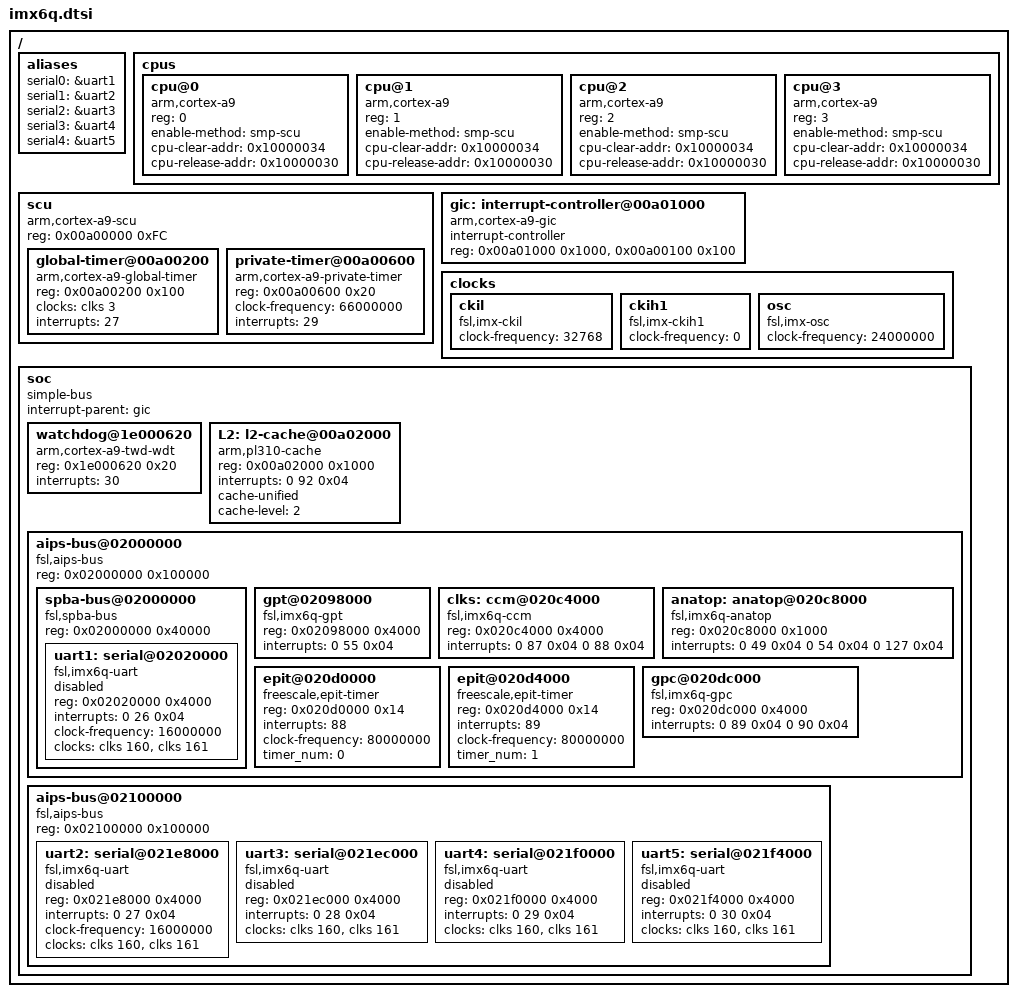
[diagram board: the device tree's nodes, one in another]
/*
 * Copyright 2014 Jimmy Durand Wesolowski - OpenWide
 * Copyright 2011 Freescale Semiconductor, Inc.
 * Copyright 2011 Linaro Ltd.
 *
 * The code contained herein is licensed under the GNU General Public
 * License. You may obtain a copy of the GNU General Public License
 * Version 2 or later at the following locations:
 *
 * http://www.opensource.org/licenses/gpl-license.html
 * http://www.gnu.org/copyleft/gpl.html
 */

/ {
	#address-cells = <1>;
	#size-cells = <1>;

	aliases {
		serial0 = &uart1;
		serial1 = &uart2;
		serial2 = &uart3;
		serial3 = &uart4;
		serial4 = &uart5;
	};

	cpus {
		#address-cells = <1>;
		#size-cells = <0>;

		cpu@0 {
			device_type = "cpu";
			compatible = "arm,cortex-a9";
			reg = <0>;
			enable-method = "smp-scu";
			cpu-clear-addr = <0x10000034>;
			cpu-release-addr = <0x10000030>;
		};

		cpu@1 {
			device_type = "cpu";
			compatible = "arm,cortex-a9";
			reg = <1>;
			enable-method = "smp-scu";
			cpu-clear-addr = <0x10000034>;
			cpu-release-addr = <0x10000030>;
		};

		cpu@2 {
			device_type = "cpu";
			compatible = "arm,cortex-a9";
			reg = <2>;
			enable-method = "smp-scu";
			cpu-clear-addr = <0x10000034>;
			cpu-release-addr = <0x10000030>;
		};

		cpu@3 {
			device_type = "cpu";
			compatible = "arm,cortex-a9";
			reg = <3>;
			enable-method = "smp-scu";
			cpu-clear-addr = <0x10000034>;
			cpu-release-addr = <0x10000030>;
		};
	};

	scu { /* Snoop Control Unit */
      		device_type = "scu";
      		compatible = "arm,cortex-a9-scu";
      		reg = <0x00a00000 0xFC>;
		#address-cells = <1>;
		#size-cells = <1>;
		ranges;

		global-timer@00a00200 {
			/* http://infocenter.arm.com/help/index.jsp?
			   topic=/com.arm.doc.ddi0407f/CIHGECHJ.html */
			/* Note that the reg attribute expects 2 sets */
			compatible = "arm,cortex-a9-global-timer";
			reg = <0x00a00200 0x100>;
			clocks = <&clks 3>;
			interrupts = <27>;
		};

		private-timer@00a00600 {
			/*http://infocenter.arm.com/help/index.jsp?
			  topic=/com.arm.doc.ddi0407f/JHBHIGCC.html */
			compatible = "arm,cortex-a9-private-timer";
			reg = <0x00a00600 0x20>;
			clock-frequency = <66000000>;
			interrupts = <29>;
		};

	};

	gic: interrupt-controller@00a01000 {
      		device_type = "pic";
		compatible = "arm,cortex-a9-gic";
		#interrupt-cells = <3>;
		#address-cells = <1>;
		#size-cells = <1>;
		interrupt-controller;
		reg = <0x00a01000 0x1000>,
		      <0x00a00100 0x100>;
	};

	clocks {
		#address-cells = <1>;
		#size-cells = <0>;

		ckil {
			compatible = "fsl,imx-ckil", "fixed-clock";
			clock-frequency = <32768>;
		};

		ckih1 {
			compatible = "fsl,imx-ckih1", "fixed-clock";
			clock-frequency = <0>;
		};

		osc {
			compatible = "fsl,imx-osc", "fixed-clock";
			clock-frequency = <24000000>;
		};
	};

	soc {
		#address-cells = <1>;
		#size-cells = <1>;
		compatible = "simple-bus";
		interrupt-parent = <&gic>;
		ranges;

		watchdog@1e000620 {
			compatible = "arm,cortex-a9-twd-wdt";
			reg = <0x1e000620 0x20>;
			interrupts = <30>;
		};

		L2: l2-cache@00a02000 {
			compatible = "arm,pl310-cache";
			reg = <0x00a02000 0x1000>;
			interrupts = <0 92 0x04>;
			cache-unified;
			cache-level = <2>;
		};

		aips-bus@02000000 { /* AIPS1 */
			compatible = "fsl,aips-bus", "simple-bus";
			#address-cells = <1>;
			#size-cells = <1>;
			reg = <0x02000000 0x100000>;
			ranges;

			spba-bus@02000000 {
				compatible = "fsl,spba-bus", "simple-bus";
				#address-cells = <1>;
				#size-cells = <1>;
				reg = <0x02000000 0x40000>;
				ranges;

				uart1: serial@02020000 {
					compatible = "fsl,imx6q-uart", "freescale,imx-uart";
					reg = <0x02020000 0x4000>;
					interrupts = <0 26 0x04>;
					clock-frequency = <16000000>;
					clocks = <&clks 160>, <&clks 161>;
					clock-names = "ipg", "per";
					status = "enabled";
				};
			};

			gpt@02098000 {
				compatible = "fsl,imx6q-gpt";
				reg = <0x02098000 0x4000>;
				interrupts = <0 55 0x04>;
			};

			clks: ccm@020c4000 {
				compatible = "fsl,imx6q-ccm";
				reg = <0x020c4000 0x4000>;
				interrupts = <0 87 0x04 0 88 0x04>;
				#clock-cells = <1>;
			};

			anatop: anatop@020c8000 {
				compatible = "fsl,imx6q-anatop", "syscon", "simple-bus";
				reg = <0x020c8000 0x1000>;
				interrupts = <0 49 0x04 0 54 0x04 0 127 0x04>;
			};

			epit@020d0000 {
				device_type = "epit1";
				compatible = "freescale,epit-timer";
				reg = <0x020d0000 0x14>;
				/* interrupts = <0 56 0x04>; */
				interrupts = <88>;
				clock-frequency = <80000000>;
				timer_num = <0>;
			};

			epit@020d4000 {
				device_type = "epit2";
				compatible = "freescale,epit-timer";
				reg = <0x020d4000 0x14>;
				/* interrupts = <0 57 0x04>; */
				interrupts = <89>;
				clock-frequency = <80000000>;
				timer_num = <1>;
			};

			gpc@020dc000 {
				compatible = "fsl,imx6q-gpc";
				reg = <0x020dc000 0x4000>;
				interrupts = <0 89 0x04 0 90 0x04>;
			};
		};

		aips-bus@02100000 { /* AIPS2 */
			compatible = "fsl,aips-bus", "simple-bus";
			#address-cells = <1>;
			#size-cells = <1>;
			reg = <0x02100000 0x100000>;
			ranges;

			uart2: serial@021e8000 {
				compatible = "fsl,imx6q-uart", "freescale,imx-uart";
				reg = <0x021e8000 0x4000>;
				interrupts = <0 27 0x04>;
				clock-frequency = <16000000>;
				clocks = <&clks 160>, <&clks 161>;
				clock-names = "ipg", "per";
				status = "enabled";
			};

			uart3: serial@021ec000 {
				compatible = "fsl,imx6q-uart", "freescale,imx-uart";
				reg = <0x021ec000 0x4000>;
				interrupts = <0 28 0x04>;
				clocks = <&clks 160>, <&clks 161>;
				clock-names = "ipg", "per";
				status = "disabled";
			};

			uart4: serial@021f0000 {
				compatible = "fsl,imx6q-uart", "freescale,imx-uart";
				reg = <0x021f0000 0x4000>;
				interrupts = <0 29 0x04>;
				clocks = <&clks 160>, <&clks 161>;
				clock-names = "ipg", "per";
				status = "disabled";
			};

			uart5: serial@021f4000 {
				compatible = "fsl,imx6q-uart", "freescale,imx-uart";
				reg = <0x021f4000 0x4000>;
				interrupts = <0 30 0x04>;
				clocks = <&clks 160>, <&clks 161>;
				clock-names = "ipg", "per";
				status = "disabled";
			};
		};
	};
};
